# C7X256V0_CORE0 register map
Vendor: Texas Instruments
Peripheral module from a debugger description file (folder J722S).
Registers are 32-bit, read-only, reset values left out (the file's numbers can be read two ways) unless marked. A register's access mark holds for its fields unless they carry their own. Offsets are as the file gives them; lines under a group give offsets from that group; [hi:lo] are bit positions; {n}, {i} and the like mark numbered series; 'fields as' and 'values as' point back to an identical list; <NAME> marks a mode.

## C7X256V0_CORE0
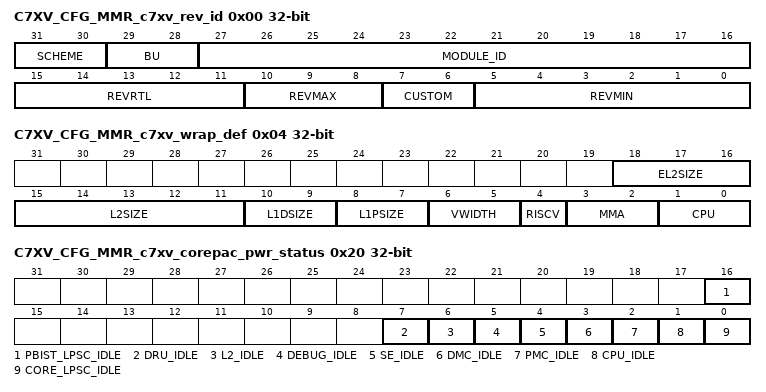
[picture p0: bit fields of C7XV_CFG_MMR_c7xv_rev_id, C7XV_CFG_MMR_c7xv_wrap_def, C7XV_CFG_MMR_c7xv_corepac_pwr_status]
0x00 C7XV_CFG_MMR_c7xv_rev_id — Revision parameters
  [31:30] SCHEME
  [29:28] BU — Scheme
  [27:16] MODULE_ID
  [15:11] REVRTL — RTL version
  [10:8] REVMAX — Major version
  [7:6] CUSTOM — Custom version
  [5:0] REVMIN — Minor version
0x04 C7XV_CFG_MMR_c7xv_wrap_def — Definition parameters
  [18:16] EL2SIZE
  [15:11] L2SIZE
  [10:9] L1DSIZE
  [8:7] L1PSIZE
  [6:5] VWIDTH — Vector width size
  [4] RISCV — RISCV ISA supported
  [3:2] MMA — MMA type
  [1:0] CPU — CPU type
0x10 C7XV_CFG_MMR_c7xv_reset_boot_vec_l — C7xV wrap reset boot vector Register LSBs
  [31:0] RESET_BASE_VECTOR_LO — RVBARADDR0[31:0]
0x14 C7XV_CFG_MMR_c7xv_reset_boot_vec_h — C7xV wrap reset boot vector Register MSBs
  [31:0] RESET_BASE_VECTOR_HI — RVBARADDR0[48:32]
0x18 C7XV_CFG_MMR_c7xv_corepac_cfg — C7xV wrap corepac configuration register
  [0] CPU_SYS_RISCV_MODE — Enables CPU booting in RISC-V mode, default is C7xVISA mode
0x1C C7XV_CFG_MMR_c7xv_corepac_pwr_cfg access not given — nfiguration register
0x20 C7XV_CFG_MMR_c7xv_corepac_pwr_status — C7xV wrap corepac power status register
  [16] PBIST_LPSC_IDLE — PBIST LPSC idle status
  [7] DRU_IDLE — L2 idle status
  [6] L2_IDLE — L2 idle status
  [5] DEBUG_IDLE — Debug idle status
  [4] SE_IDLE — SE idle status
  [3] DMC_IDLE — DMC idle status
  [2] PMC_IDLE — PMC idle status
  [1] CPU_IDLE — CPU idle status
  [0] CORE_LPSC_IDLE — Core LPSC idle status
